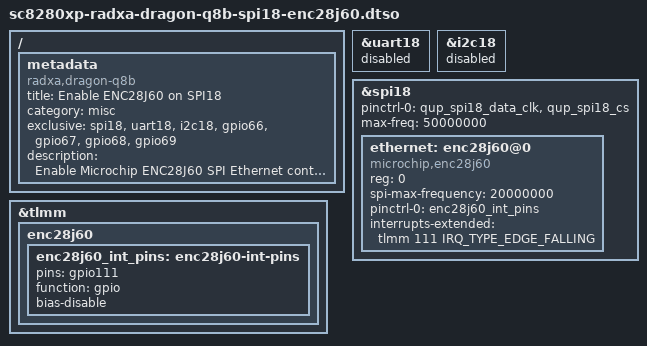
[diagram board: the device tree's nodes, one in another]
// SPDX-License-Identifier: BSD-3-Clause
/*
 * Copyright (c) 2026 Radxa Computer (Shenzhen) Co., Ltd.
 */

/dts-v1/;
/plugin/;

#include <dt-bindings/interrupt-controller/irq.h>

/ {
	metadata {
		title = "Enable ENC28J60 on SPI18";
		compatible = "radxa,dragon-q8b";
		category = "misc";
		exclusive = "spi18", "uart18", "i2c18", "gpio66", "gpio67", "gpio68", "gpio69";
		description = "Enable Microchip ENC28J60 SPI Ethernet controller on SPI18.
INT=11";
	};
};

&uart18 {
	status = "disabled";
};

&i2c18 {
	status = "disabled";
};

&spi18 {
	pinctrl-0 = <&qup_spi18_data_clk>, <&qup_spi18_cs>;
	pinctrl-names = "default";
	max-freq = <50000000>;
	
	status = "okay";

	ethernet: enc28j60@0 {
		compatible = "microchip,enc28j60";
		reg = <0>;
		spi-max-frequency = <20000000>;

		pinctrl-names = "default";
		pinctrl-0 = <&enc28j60_int_pins>;

		interrupts-extended = <&tlmm 111 IRQ_TYPE_EDGE_FALLING>;
	};
};

&tlmm {
	enc28j60 {
		enc28j60_int_pins: enc28j60-int-pins {
			pins = "gpio111";
			function = "gpio";
			bias-disable;
		};
	};
};
